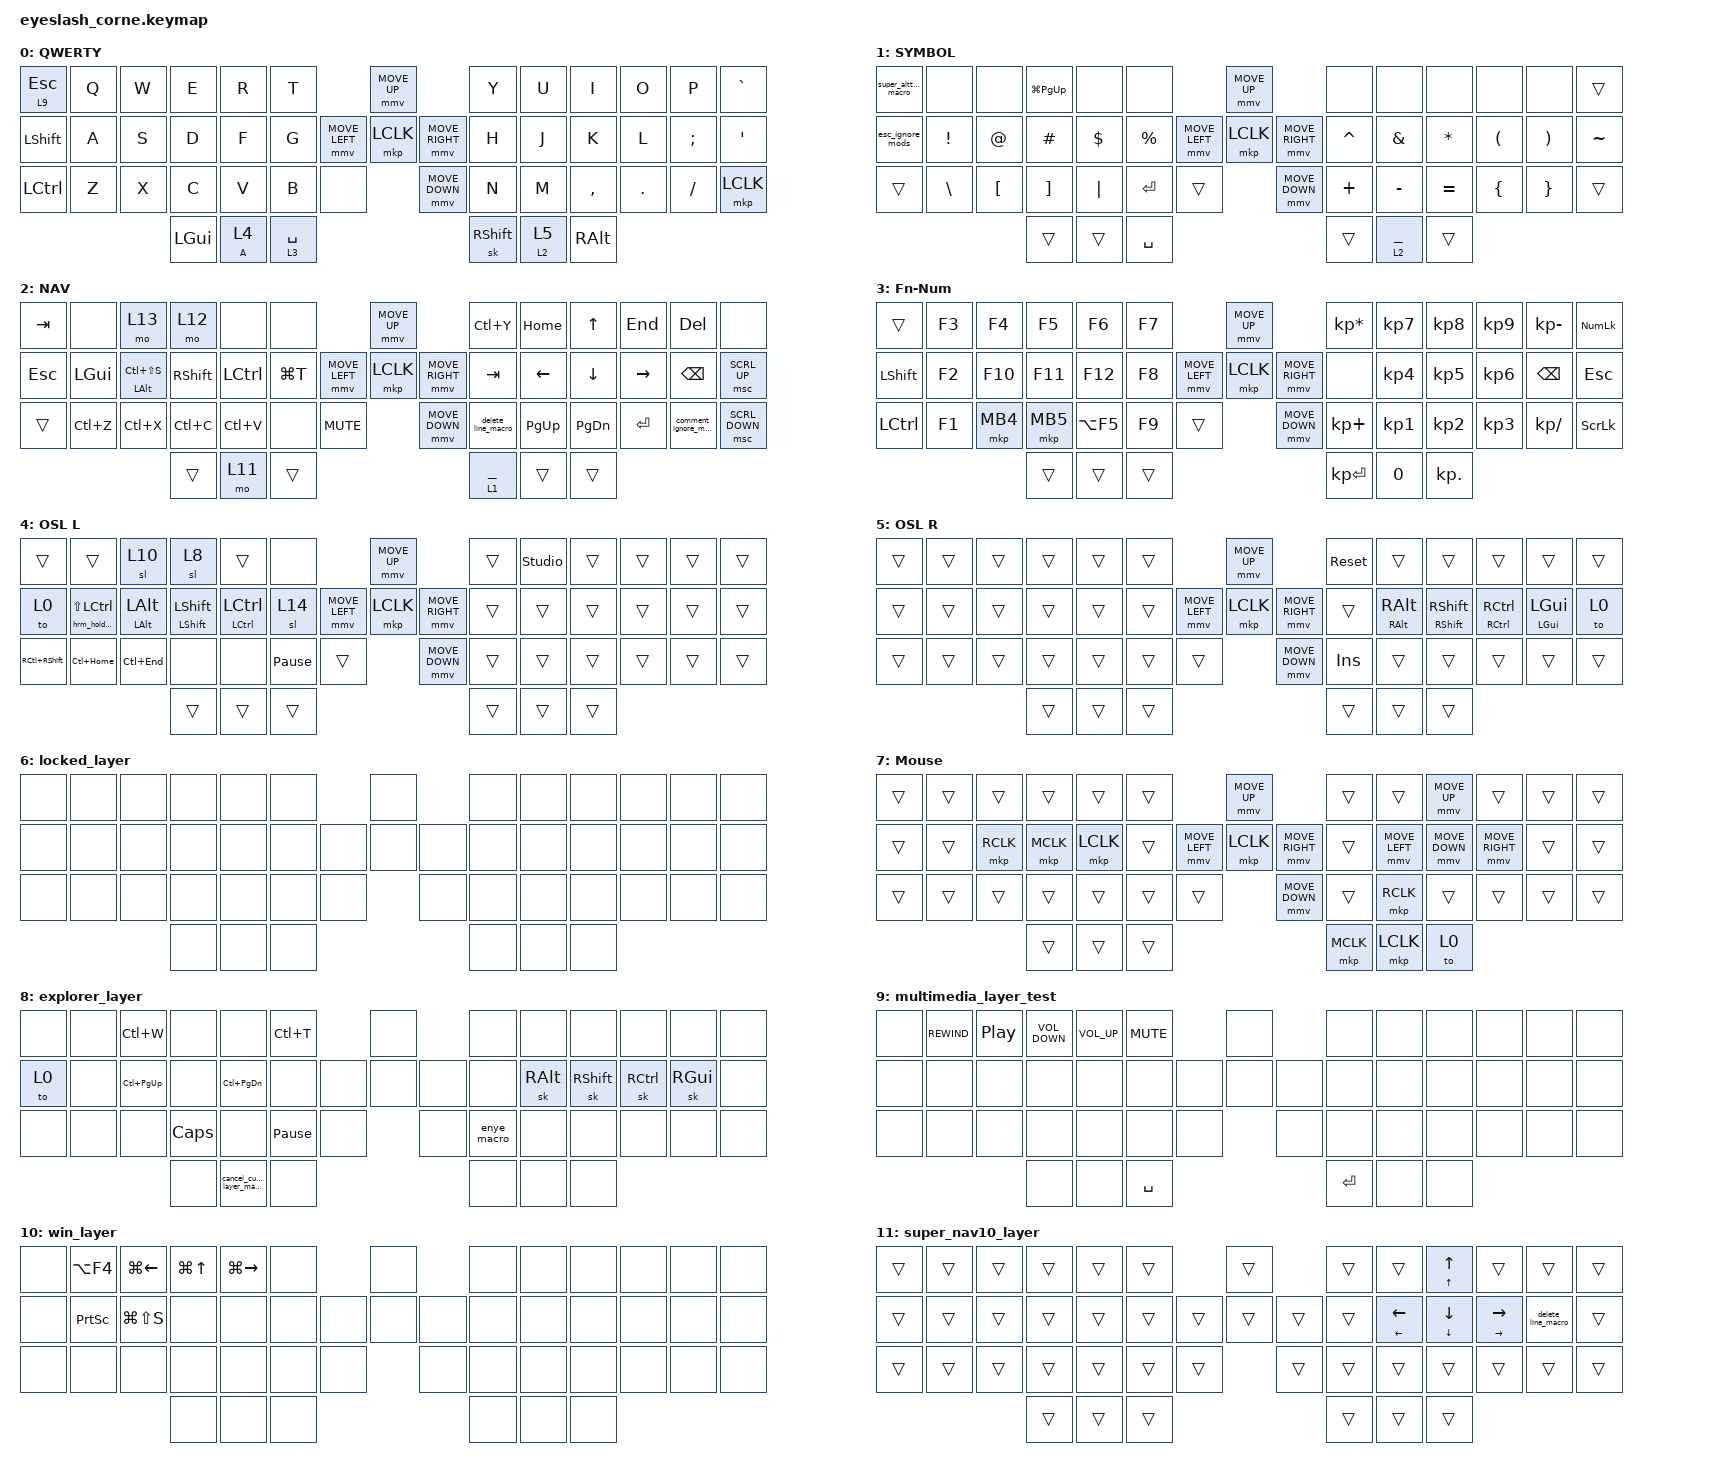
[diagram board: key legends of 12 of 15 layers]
#include <behaviors.dtsi>
#include <input/processors.dtsi>
#include <dt-bindings/zmk/bt.h>
#include <dt-bindings/zmk/keys.h>
#include <dt-bindings/zmk/mouse.h>
#include <dt-bindings/zmk/outputs.h>
#include <dt-bindings/zmk/rgb.h>
#include <dt-bindings/zmk/pointing.h>

#include <input/processors.dtsi>

/*

   &mmv_input_listener {
       input-processors = <&zip_xy_scaler 2 1>;
   };

   &msc_input_listener {
       input-processors = <&zip_xy_scaler 2 1>;
   };

 */

#define ZMK_MOUSE_DEFAULT_MOVE_VAL 1200  // 600
#define ZMK_MOUSE_DEFAULT_SCRL_VAL 20    // 10

&sl {
    release-after-ms = <5000>;
    ignore-modifiers;
};

&sk {
    release-after-ms = <5000>;
    quick-release;
    ignore-modifiers;
};

/ {
    behaviors {
        oslr: behavior_mo_tog {
            compatible = "zmk,behavior-hold-tap";
            #binding-cells = <2>;
            flavor = "hold-preferred";
            tapping-term-ms = <200>;
            bindings = <&mo>, <&sl>;
        };

        layer_tap_release_alttab: layer_tap_release_alttab {
            compatible = "zmk,behavior-hold-tap";
            label = "LAYER_TAP_RELEASE_ALTTAB";
            bindings = <&mo_release_alt_macro>, <&sl>;

            #binding-cells = <2>;
            flavor = "hold-preferred";
            tapping-term-ms = <200>;
        };

        hrm_behavior: hrm_behavior {
            compatible = "zmk,behavior-hold-tap";
            label = "HRM_BEHAVIOR";
            bindings = <&sk>, <&sk_hrm_macro>;

            #binding-cells = <2>;
            tapping-term-ms = <200>;
        };

        comment_ignore_mods: comment_ignore_mods {
            compatible = "zmk,behavior-mod-morph";
            label = "COMMENT_IGNORE_MODS";
            bindings = <&kp LC(SLASH)>, <&kp LC(SLASH)>;

            #binding-cells = <0>;
            mods = <(MOD_LALT|MOD_LSFT|MOD_RALT|MOD_RSFT)>;
        };

        esc_ignore_mods: esc_ignore_mods {
            compatible = "zmk,behavior-mod-morph";
            label = "ESC_IGNORE_MODS";
            bindings = <&kp ESCAPE>, <&kp ESCAPE>;

            #binding-cells = <0>;
            mods = <(MOD_LSFT|MOD_LCTL|MOD_LALT|MOD_LGUI|MOD_RCTL|MOD_RSFT|MOD_RALT|MOD_RGUI)>;
        };

        sk_noignore: sk_noignore {
            compatible = "zmk,behavior-sticky-key";
            label = "SK_NOIGNORE";
            bindings = <&sk>;
            #binding-cells = <1>;
            release-after-ms = <5000>;
            lazy;
            quick-release;
        };

        super_arrow_behavior: super_arrow_behavior {
            compatible = "zmk,behavior-hold-tap";
            label = "SUPER_ARROW_BEHAVIOR";
            bindings = <&kp>, <&move_arrow_10_macro>;

            #binding-cells = <2>;
            tapping-term-ms = <200>;
        };

        super_arrow_x2_behavior: super_arrow_x2_behavior {
            compatible = "zmk,behavior-hold-tap";
            label = "SUPER_ARROW_X2_BEHAVIOR";
            bindings = <&kp>, <&move_arrow_20_macro>;

            #binding-cells = <2>;
            tapping-term-ms = <200>;
        };

        super_arrow_xhalf_behavior: super_arrow_xhalf_behavior {
            compatible = "zmk,behavior-hold-tap";
            label = "SUPER_ARROW_XHALF_BEHAVIOR";
            bindings = <&kp>, <&move_arrow_5_macro>;

            #binding-cells = <2>;
            tapping-term-ms = <200>;
        };
    };

    macros {
        super_alttab_macro: super_alttab {
            compatible = "zmk,behavior-macro";
            #binding-cells = <0>;
            bindings =
                <&macro_press>,
                <&kp LALT>,
                <&macro_tap>,
                <&kp TAB &to 2>;
        };

        select_line_macro: new_macro {
            compatible = "zmk,behavior-macro";
            #binding-cells = <0>;
            bindings =
                <&macro_tap>,
                <&kp HOME>,
                <&macro_press>,
                <&kp LEFT_SHIFT>,
                <&macro_tap>,
                <&kp END>,
                <&macro_release>,
                <&kp LEFT_SHIFT>;

            label = "NEW_MACRO";
        };

        mo_release_alt_macro: alt_2_macro {
            compatible = "zmk,behavior-macro";
            #binding-cells = <0>;
            bindings =
                <&macro_tap>,
                <&to 1>,
                <&macro_pause_for_release>,
                <&macro_release>,
                <&kp LEFT_ALT>,
                <&macro_tap>,
                <&to 0>;

            label = "alt_2_macro";
        };

        sk_hrm_macro: mo_hrm {
            compatible = "zmk,behavior-macro-one-param";
            #binding-cells = <1>;
            bindings =
                <&macro_tap>,
                <&macro_param_1to1 &sk MACRO_PLACEHOLDER>,
                <&macro_pause_for_release>,
                <&macro_tap>,
                <&to 0>;

            label = "MO_HRM";
        };

        cancel_custom_layer_macro: cancel_custom_activation {
            compatible = "zmk,behavior-macro";
            #binding-cells = <0>;
            bindings = <&macro_tap>, <&to 0>, <&macro_tap>, <&sl 4>;

            label = "CANCEL_CUSTOM_ACTIVATION";
        };

        enye_macro: enye {
            compatible = "zmk,behavior-macro";
            #binding-cells = <0>;
            bindings =
                <&macro_press>,
                <&kp LEFT_ALT>,
                <&macro_tap>,
                <&kp KP_N1 &kp KP_NUMBER_6 &kp KP_NUMBER_4>,
                <&macro_release>,
                <&kp LEFT_ALT>;

            label = "ENYE";
        };

        to_base_and_escape_macro: to_base_and_escape {
            compatible = "zmk,behavior-macro";
            #binding-cells = <0>;
            bindings = <&macro_tap>, <&to 0 &kp ESCAPE>;

            label = "TO_BASE_AND_ESCAPE";
        };

        hrm_hold_macro: hrm_hold_macro {
            compatible = "zmk,behavior-macro-one-param";
            #binding-cells = <1>;
            bindings =
                <&macro_press>,
                <&macro_param_1to1 &kp MACRO_PLACEHOLDER>,
                <&macro_tap>,
                <&to 0>,
                <&macro_pause_for_release>,
                <&macro_release>,
                <&macro_param_1to1 &kp MACRO_PLACEHOLDER>;

            label = "hrm_hold_macro";
        };

        delete_line_macro: delete_line_macro {
            compatible = "zmk,behavior-macro";
            #binding-cells = <0>;
            bindings =
                <&macro_tap>,
                <&kp HOME>,
                <&macro_press>,
                <&kp LEFT_SHIFT>,
                <&macro_tap>,
                <&kp END>,
                <&macro_release>,
                <&kp LEFT_SHIFT>,
                <&macro_tap>,
                <&kp BACKSPACE &kp BACKSPACE>;

            label = "DELETE_LINE_MACRO";
        };

        move_arrow_10_macro: move_arrow_20_macro {
            compatible = "zmk,behavior-macro-one-param";
            #binding-cells = <1>;
            bindings =
                <&macro_tap>,
                <&macro_param_1to1 &kp MACRO_PLACEHOLDER &key_repeat &key_repeat &key_repeat &key_repeat &key_repeat &key_repeat &key_repeat &key_repeat &key_repeat>;

            label = "MOVE_ARROW_20_MACRO";
            wait-ms = <5>;
            tap-ms = <5>;
        };

        move_arrow_20_macro: move_arrow_10_macro {
            compatible = "zmk,behavior-macro-one-param";
            #binding-cells = <1>;
            bindings =
                <&macro_tap>,
                <&macro_param_1to1 &kp MACRO_PLACEHOLDER &key_repeat &key_repeat &key_repeat &key_repeat &key_repeat &key_repeat &key_repeat &key_repeat &key_repeat &key_repeat &key_repeat &key_repeat &key_repeat &key_repeat &key_repeat &key_repeat &key_repeat &key_repeat &key_repeat>;

            label = "MOVE_ARROW_10_MACRO";
            wait-ms = <5>;
            tap-ms = <5>;
        };

        move_arrow_5_macro: move_arrow_5_macro {
            compatible = "zmk,behavior-macro-one-param";
            #binding-cells = <1>;
            bindings =
                <&macro_tap>,
                <&macro_param_1to1 &kp MACRO_PLACEHOLDER &key_repeat &key_repeat &key_repeat &key_repeat>;

            label = "MOVE_ARROW_5_MACRO";
            wait-ms = <5>;
            tap-ms = <5>;
        };
    };

    rgb_encoder: rgb_encoder {
        compatible = "zmk,behavior-sensor-rotate";
        #sensor-binding-cells = <0>;
        bindings = <&rgb_ug RGB_BRI>, <&rgb_ug RGB_BRD>;
    };

    scroll_encoder: scroll_encoder {
        compatible = "zmk,behavior-sensor-rotate";
        #sensor-binding-cells = <0>;
        bindings = <&msc SCRL_DOWN>, <&msc SCRL_UP>;

        tap-ms = <30>;
    };

    combos {
        compatible = "zmk,combos";

        unlock_combo {
            bindings = <&to 0>;
            key-positions = <1 5>;
            layers = <6>;
        };

        lock_combo {
            bindings = <&to 6>;
            key-positions = <1 5>;
            layers = <0>;
        };

        numpad_osl_activator {
            bindings = <&sl 5>;
            key-positions = <38 39>;
            layers = <3 1>;
        };

        func_osl_activator {
            bindings = <&sl 4>;
            key-positions = <30 31>;
            layers = <3 1>;
        };

        boot_left {
            bindings = <&bootloader>;
            key-positions = <2 4>;
            layers = <4>;
        };

        boot_right {
            bindings = <&bootloader>;
            key-positions = <8 10>;
            layers = <5>;
        };

        reset_left {
            bindings = <&sys_reset>;
            key-positions = <30 32>;
            layers = <4>;
        };

        reset_right {
            bindings = <&sys_reset>;
            key-positions = <39 37>;
            layers = <5>;
        };
    };

    keymap {
        compatible = "zmk,keymap";

        base_layer {
            display-name = "QWERTY";
            bindings = <
&lt 9 ESCAPE    &kp Q  &kp W  &kp E     &kp R                          &kp T                                 &mmv MOVE_UP                     &kp Y       &kp U      &kp I      &kp O    &kp P     &kp GRAVE
&kp LEFT_SHIFT  &kp A  &kp S  &kp D     &kp F                          &kp G                 &mmv MOVE_LEFT  &mkp LCLK       &mmv MOVE_RIGHT  &kp H       &kp J      &kp K      &kp L    &kp SEMI  &kp SQT
&kp LCTRL       &kp Z  &kp X  &kp C     &kp V                          &kp B        &none                    &mmv MOVE_DOWN                   &kp N       &kp M      &kp COMMA  &kp DOT  &kp FSLH  &mkp LCLK
                              &kp LGUI  &layer_tap_release_alttab A 4  &lt 3 SPACE                                                            &sk RSHIFT  &oslr 2 5  &kp RALT
            >;

            sensor-bindings = <&inc_dec_kp C_VOLUME_UP C_VOLUME_DOWN>;
        };

        sym_layer {
            display-name = "SYMBOL";
            bindings = <
&super_alttab_macro  &none          &none             &kp LG(PAGE_UP)    &none     &none                                &mmv MOVE_UP                     &none      &none             &none      &none           &none            &trans
&esc_ignore_mods     &kp EXCL       &kp AT            &kp HASH           &kp DLLR  &kp PRCNT            &mmv MOVE_LEFT  &mkp LCLK       &mmv MOVE_RIGHT  &kp CARET  &kp AMPS          &kp ASTRK  &kp LPAR        &kp RPAR         &kp TILDE
&trans               &kp BACKSLASH  &kp LEFT_BRACKET  &kp RIGHT_BRACKET  &kp PIPE  &kp ENTER  &trans                    &mmv MOVE_DOWN                   &kp PLUS   &kp MINUS         &kp EQUAL  &kp LEFT_BRACE  &kp RIGHT_BRACE  &trans
                                                      &trans             &trans    &kp SPACE                                                             &trans     &lt 2 UNDERSCORE  &trans
            >;

            sensor-bindings = <&scroll_encoder>;
        };

        nav_layer {
            display-name = "NAV";
            bindings = <
&kp TAB     &none         &mo 13              &mo 12      &none      &none                                    &mmv MOVE_UP                     &kp LC(Y)           &kp HOME   &kp UP     &kp END    &kp DELETE            &none
&kp ESCAPE  &kp LEFT_GUI  &mt LALT LC(LS(S))  &kp RSHIFT  &kp LCTRL  &kp LG(T)                &mmv MOVE_LEFT  &mkp LCLK       &mmv MOVE_RIGHT  &kp TAB             &kp LEFT   &kp DOWN   &kp RIGHT  &kp BSPC              &msc SCRL_UP
&trans      &kp LC(Z)     &kp LC(X)           &kp LC(C)   &kp LC(V)  &none      &kp C_MUTE                    &mmv MOVE_DOWN                   &delete_line_macro  &kp PG_UP  &kp PG_DN  &kp RET    &comment_ignore_mods  &msc SCRL_DOWN
                                              &trans      &mo 11     &trans                                                                    &lt 1 UNDERSCORE    &trans     &trans
            >;

            sensor-bindings = <&scroll_encoder>;
        };

        fn_num_layer {
            display-name = "Fn-Num";
            bindings = <
&trans            &kp F3  &kp F4    &kp F5    &kp F6      &kp F7                            &mmv MOVE_UP                     &kp KP_MULTIPLY  &kp KP_N7  &kp KP_N8   &kp KP_N9  &kp KP_MINUS   &kp KP_NUMLOCK
&kp LEFT_SHIFT    &kp F2  &kp F10   &kp F11   &kp F12     &kp F8            &mmv MOVE_LEFT  &mkp LCLK       &mmv MOVE_RIGHT  &none            &kp KP_N4  &kp KP_N5   &kp KP_N6  &kp BSPC       &kp ESCAPE
&kp LEFT_CONTROL  &kp F1  &mkp MB4  &mkp MB5  &kp LA(F5)  &kp F9  &trans                    &mmv MOVE_DOWN                   &kp KP_PLUS      &kp KP_N1  &kp KP_N2   &kp KP_N3  &kp KP_DIVIDE  &kp SCROLLLOCK
                                    &trans    &trans      &trans                                                             &kp KP_ENTER     &kp N0     &kp KP_DOT
            >;

            sensor-bindings = <&scroll_encoder>;
        };

        osl_l_layer {
            display-name = "OSL L";
            bindings = <
&trans         &trans                            &sl 10                   &sl 8                      &trans                     &none                                      &mmv MOVE_UP                     &trans  &studio_unlock  &trans  &trans  &trans  &trans
&to 0          &hrm_hold_macro LS(LEFT_CONTROL)  &hrm_behavior LALT LALT  &hrm_behavior LSHFT LSHFT  &hrm_behavior LCTRL LCTRL  &sl 14                     &mmv MOVE_LEFT  &mkp LCLK       &mmv MOVE_RIGHT  &trans  &trans          &trans  &trans  &trans  &trans
&kp RC(RSHFT)  &kp LC(HOME)                      &kp LC(END)              &none                      &none                      &kp PAUSE_BREAK  &trans                    &mmv MOVE_DOWN                   &trans  &trans          &trans  &trans  &trans  &trans
                                                                          &trans                     &trans                     &trans                                                                      &trans  &trans          &trans
            >;

            sensor-bindings = <&scroll_encoder>;
        };

        ols_r_layer {
            display-name = "OSL R";
            bindings = <
&trans  &trans  &trans  &trans  &trans  &trans                            &mmv MOVE_UP                     &sys_reset  &trans                   &trans                       &trans                     &trans                           &trans
&trans  &trans  &trans  &trans  &trans  &trans            &mmv MOVE_LEFT  &mkp LCLK       &mmv MOVE_RIGHT  &trans      &hrm_behavior RALT RALT  &hrm_behavior RSHIFT RSHIFT  &hrm_behavior RCTRL RCTRL  &hrm_behavior LEFT_GUI LEFT_GUI  &to 0
&trans  &trans  &trans  &trans  &trans  &trans  &trans                    &mmv MOVE_DOWN                   &kp INSERT  &trans                   &trans                       &trans                     &trans                           &trans
                        &trans  &trans  &trans                                                             &trans      &trans                   &trans
            >;

            sensor-bindings = <&scroll_encoder>;
        };

        locked_layer {
            bindings = <
&none  &none  &none  &none  &none  &none                  &none         &none  &none  &none  &none  &none  &none
&none  &none  &none  &none  &none  &none           &none  &none  &none  &none  &none  &none  &none  &none  &none
&none  &none  &none  &none  &none  &none  &none           &none         &none  &none  &none  &none  &none  &none
                     &none  &none  &none                                &none  &none  &none
            >;
        };

        mouse_layer {
            display-name = "Mouse";
            bindings = <
&trans  &trans  &trans     &trans     &trans     &trans                            &mmv MOVE_UP                     &trans     &trans          &mmv MOVE_UP    &trans           &trans  &trans
&trans  &trans  &mkp RCLK  &mkp MCLK  &mkp LCLK  &trans            &mmv MOVE_LEFT  &mkp LCLK       &mmv MOVE_RIGHT  &trans     &mmv MOVE_LEFT  &mmv MOVE_DOWN  &mmv MOVE_RIGHT  &trans  &trans
&trans  &trans  &trans     &trans     &trans     &trans  &trans                    &mmv MOVE_DOWN                   &trans     &mkp RCLK       &trans          &trans           &trans  &trans
                           &trans     &trans     &trans                                                             &mkp MCLK  &mkp LCLK       &to 0
            >;

            sensor-bindings = <&scroll_encoder>;
        };

        explorer_layer {
            bindings = <
&none  &none  &kp LC(W)        &none     &none                       &kp LC(T)                        &none         &none        &none     &none      &none      &none     &none
&to 0  &none  &kp LC(PAGE_UP)  &none     &kp LC(PAGE_DOWN)           &none                     &none  &none  &none  &none        &sk RALT  &sk RSHFT  &sk RCTRL  &sk RGUI  &none
&none  &none  &none            &kp CAPS  &none                       &kp PAUSE_BREAK  &none           &none         &enye_macro  &none     &none      &none      &none     &none
                               &none     &cancel_custom_layer_macro  &none                                          &none        &none     &none
            >;
        };

        multimedia_layer_test {
            bindings = <
&none  &kp C_REWIND  &kp C_PLAY_PAUSE  &kp C_VOLUME_DOWN  &kp C_VOLUME_UP  &kp C_MUTE                  &none         &none       &none  &none  &none  &none  &none
&none  &none         &none             &none              &none            &none                &none  &none  &none  &none       &none  &none  &none  &none  &none
&none  &none         &none             &none              &none            &none       &none           &none         &none       &none  &none  &none  &none  &none
                                       &none              &none            &kp SPACE                                 &kp RETURN  &none  &none
            >;
        };

        windows_layer {
            bindings = <
&none  &kp LA(F4)       &kp LG(LEFT)   &kp LG(UP_ARROW)  &kp LG(RIGHT)  &none                  &none         &none  &none  &none  &none  &none  &none
&none  &kp PRINTSCREEN  &kp LG(LS(S))  &none             &none          &none           &none  &none  &none  &none  &none  &none  &none  &none  &none
&none  &none            &none          &none             &none          &none  &none           &none         &none  &none  &none  &none  &none  &none
                                       &none             &none          &none                                &none  &none  &none
            >;

            label = "win_layer";
        };

        super_nav10_layer {
            bindings = <
&trans  &trans  &trans  &trans  &trans  &trans                    &trans          &trans  &trans                                          &super_arrow_behavior UP_ARROW UP_ARROW      &trans                                            &trans              &trans
&trans  &trans  &trans  &trans  &trans  &trans            &trans  &trans  &trans  &trans  &super_arrow_x2_behavior LEFT_ARROW LEFT_ARROW  &super_arrow_behavior DOWN_ARROW DOWN_ARROW  &super_arrow_x2_behavior RIGHT_ARROW RIGHT_ARROW  &delete_line_macro  &trans
&trans  &trans  &trans  &trans  &trans  &trans  &trans            &trans          &trans  &trans                                          &trans                                       &trans                                            &trans              &trans
                        &trans  &trans  &trans                                    &trans  &trans                                          &trans
            >;
        };

        super_nav20_layer {
            bindings = <
&trans  &trans  &trans  &trans  &trans  &trans                    &trans          &trans  &trans                                          &super_arrow_x2_behavior UP_ARROW UP_ARROW      &trans                                            &trans              &trans
&trans  &trans  &trans  &trans  &trans  &trans            &trans  &trans  &trans  &trans  &super_arrow_x2_behavior LEFT_ARROW LEFT_ARROW  &super_arrow_x2_behavior DOWN_ARROW DOWN_ARROW  &super_arrow_x2_behavior RIGHT_ARROW RIGHT_ARROW  &delete_line_macro  &trans
&trans  &trans  &trans  &trans  &trans  &trans  &trans            &trans          &trans  &trans                                          &trans                                          &trans                                            &trans              &trans
                        &trans  &trans  &trans                                    &trans  &trans                                          &trans
            >;
        };

        super_nav5_layer {
            bindings = <
&trans  &trans  &trans  &trans  &trans  &trans                    &trans          &trans  &trans                                          &super_arrow_xhalf_behavior UP_ARROW UP_ARROW      &trans                                            &trans              &trans
&trans  &trans  &trans  &trans  &trans  &trans            &trans  &trans  &trans  &trans  &super_arrow_x2_behavior LEFT_ARROW LEFT_ARROW  &super_arrow_xhalf_behavior DOWN_ARROW DOWN_ARROW  &super_arrow_x2_behavior RIGHT_ARROW RIGHT_ARROW  &delete_line_macro  &trans
&trans  &trans  &trans  &trans  &trans  &trans  &trans            &trans          &trans  &trans                                          &trans                                             &trans                                            &trans              &trans
                        &trans  &trans  &trans                                    &trans  &trans                                          &trans
            >;
        };

        Toggle_Layer {
            bindings = <
&trans  &trans  &trans          &trans        &trans  &trans                    &trans          &trans  &trans          &kp INSERT  &trans  &trans  &trans
&trans  &trans  &kp SCROLLLOCK  &trans        &trans  &trans            &trans  &trans  &trans  &trans  &trans          &trans      &trans  &trans  &trans
&trans  &trans  &trans          &kp CAPSLOCK  &trans  &trans  &trans            &trans          &trans  &kp KP_NUMLOCK  &trans      &trans  &trans  &trans
                                &trans        &trans  &trans                                    &trans  &trans          &trans
            >;

            label = "Toggle_Layer";
        };
    };

    conditional_layers {
        compatible = "zmk,conditional-layers";

        mouselayer {
            if-layers = <2 1>;
            then-layer = <7>;
        };
    };
};
